# ATmega328P register map
File version: 1.0
Registers are 8-bit, read-write, reset 0x0 unless marked. A register's access mark holds for its fields unless they carry their own. Offsets are from the block's base; [hi:lo] are bit positions; {n}, {i} and the like mark numbered series.

## TC2 — Timer/Counter, 8-bit Async
Base 0x00800000
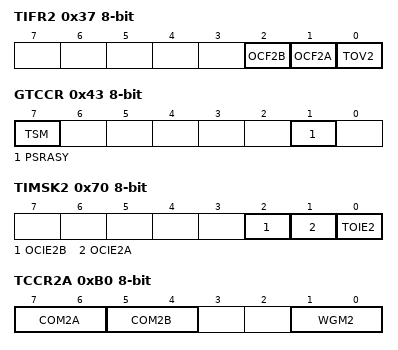
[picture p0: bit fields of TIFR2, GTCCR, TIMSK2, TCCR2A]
0x37 TIFR2 — Timer/Counter Interrupt Flag Register
  [2] OCF2B — Output Compare Flag 2B
  [1] OCF2A — Output Compare Flag 2A
  [0] TOV2 — Timer/Counter2 Overflow Flag
0x43 GTCCR — General Timer Counter Control register
  [7] TSM — Timer/Counter Synchronization Mode
  [1] PSRASY — Prescaler Reset Timer/Counter2
0x70 TIMSK2 — Timer/Counter Interrupt Mask register
  [2] OCIE2B — Timer/Counter2 Output Compare Match B Interrupt Enable
  [1] OCIE2A — Timer/Counter2 Output Compare Match A Interrupt Enable
  [0] TOIE2 — Timer/Counter2 Overflow Interrupt Enable
0xB0 TCCR2A — Timer/Counter2 Control Register A
  [7:6] COM2A — Compare Output Mode bits
  [5:4] COM2B — Compare Output Mode bits
  [1:0] WGM2 — Waveform Genration Mode
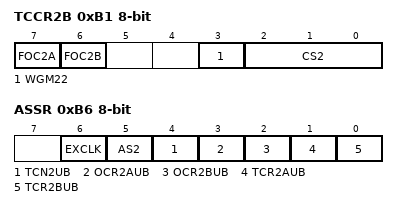
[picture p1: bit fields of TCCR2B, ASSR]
0xB1 TCCR2B — Timer/Counter2 Control Register B
  [7] FOC2A — Force Output Compare A
  [6] FOC2B — Force Output Compare B
  [3] WGM22 — Waveform Generation Mode
  [2:0] CS2 — Clock Select bits
0xB2 TCNT2 — Timer/Counter2
0xB3 OCR2A — Timer/Counter2 Output Compare Register A
0xB4 OCR2B — Timer/Counter2 Output Compare Register B
0xB6 ASSR — Asynchronous Status Register
  [6] EXCLK — Enable External Clock Input
  [5] AS2 — Asynchronous Timer/Counter2
  [4] TCN2UB — Timer/Counter2 Update Busy
  [3] OCR2AUB — Output Compare Register2 Update Busy
  [2] OCR2BUB — Output Compare Register 2 Update Busy
  [1] TCR2AUB — Timer/Counter Control Register2 Update Busy
  [0] TCR2BUB — Timer/Counter Control Register2 Update Busy

## ADC — Analog-to-Digital Converter
Base 0x00800000
0x78 ADC 16-bit (reset mask 0xFF) — ADC Data Register Bytes
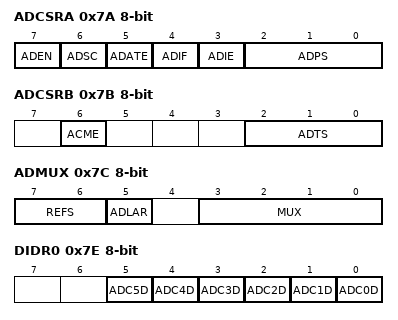
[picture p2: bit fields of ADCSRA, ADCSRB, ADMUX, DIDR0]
0x7A ADCSRA — The ADC Control and Status register A
  [7] ADEN — ADC Enable
  [6] ADSC — ADC Start Conversion
  [5] ADATE — ADC Auto Trigger Enable
  [4] ADIF — ADC Interrupt Flag
  [3] ADIE — ADC Interrupt Enable
  [2:0] ADPS — ADC Prescaler Select Bits
0x7B ADCSRB — The ADC Control and Status register B
  [6] ACME
  [2:0] ADTS — ADC Auto Trigger Source bits
0x7C ADMUX — The ADC multiplexer Selection Register
  [7:6] REFS — Reference Selection Bits
  [5] ADLAR — Left Adjust Result
  [3:0] MUX — Analog Channel Selection Bits
0x7E DIDR0 — Digital Input Disable Register
  [n] ADC{n}D (n=0..5)

## AC — Analog Comparator
Base 0x00800000
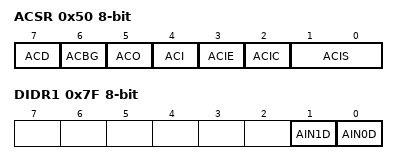
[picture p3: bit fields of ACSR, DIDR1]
0x50 ACSR — Analog Comparator Control And Status Register
  [7] ACD — Analog Comparator Disable
  [6] ACBG — Analog Comparator Bandgap Select
  [5] ACO — Analog Compare Output
  [4] ACI — Analog Comparator Interrupt Flag
  [3] ACIE — Analog Comparator Interrupt Enable
  [2] ACIC — Analog Comparator Input Capture Enable
  [1:0] ACIS — Analog Comparator Interrupt Mode Select bits
0x7F DIDR1 — Digital Input Disable Register 1
  [1] AIN1D — AIN1 Digital Input Disable
  [0] AIN0D — AIN0 Digital Input Disable

## PORTB — I/O Port
Base 0x00800000
0x23 PINB — Port B Input Pins
0x24 DDRB — Port B Data Direction Register
0x25 PORTB — Port B Data Register

## PORTC — I/O Port
Base 0x00800000
0x26 PINC — Port C Input Pins
0x27 DDRC — Port C Data Direction Register
0x28 PORTC — Port C Data Register

## PORTD — I/O Port
Base 0x00800000
0x29 PIND — Port D Input Pins
0x2A DDRD — Port D Data Direction Register
0x2B PORTD — Port D Data Register

## TC0 — Timer/Counter, 8-bit
Base 0x00800000
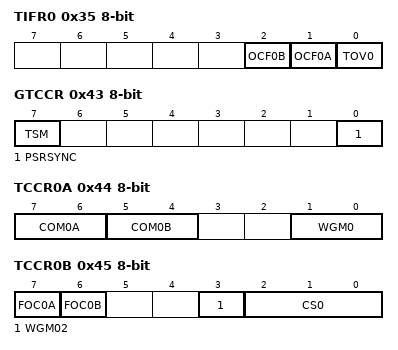
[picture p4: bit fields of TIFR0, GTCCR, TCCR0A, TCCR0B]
0x35 TIFR0 — Timer/Counter0 Interrupt Flag register
  [2] OCF0B — Timer/Counter0 Output Compare Flag 0B
  [1] OCF0A — Timer/Counter0 Output Compare Flag 0A
  [0] TOV0 — Timer/Counter0 Overflow Flag
0x43 GTCCR — General Timer/Counter Control Register
  [7] TSM — Timer/Counter Synchronization Mode
  [0] PSRSYNC — Prescaler Reset Timer/Counter1 and Timer/Counter0
0x44 TCCR0A — Timer/Counter Control Register A
  [7:6] COM0A — Compare Output Mode, Phase Correct PWM Mode
  [5:4] COM0B — Compare Output Mode, Fast PWm
  [1:0] WGM0 — Waveform Generation Mode
0x45 TCCR0B — Timer/Counter Control Register B
  [7] FOC0A — Force Output Compare A
  [6] FOC0B — Force Output Compare B
  [3] WGM02
  [2:0] CS0 — Clock Select
0x46 TCNT0 — Timer/Counter0
0x47 OCR0A — Timer/Counter0 Output Compare Register
0x48 OCR0B — Timer/Counter0 Output Compare Register
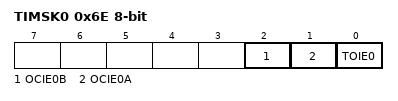
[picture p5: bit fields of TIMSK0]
0x6E TIMSK0 — Timer/Counter0 Interrupt Mask Register
  [2] OCIE0B — Timer/Counter0 Output Compare Match B Interrupt Enable
  [1] OCIE0A — Timer/Counter0 Output Compare Match A Interrupt Enable
  [0] TOIE0 — Timer/Counter0 Overflow Interrupt Enable

## EXINT — External Interrupts
Base 0x00800000
0x3B PCIFR — Pin Change Interrupt Flag Register
  [2:0] PCIF — Pin Change Interrupt Flags
0x3C EIFR — External Interrupt Flag Register
  [1:0] INTF — External Interrupt Flags
0x3D EIMSK — External Interrupt Mask Register
  [1:0] INT — External Interrupt Request 1 Enable
0x68 PCICR — Pin Change Interrupt Control Register
  [2:0] PCIE — Pin Change Interrupt Enables
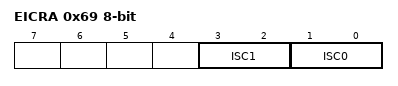
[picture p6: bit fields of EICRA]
0x69 EICRA — External Interrupt Control Register
  [3:2] ISC1 — External Interrupt Sense Control 1 Bits
  [1:0] ISC0 — External Interrupt Sense Control 0 Bits
0x6B PCMSK0 — Pin Change Mask Register 0
  [7:0] PCINT — Pin Change Enable Masks
0x6C PCMSK1 — Pin Change Mask Register 1
  [6:0] PCINT — Pin Change Enable Masks
0x6D PCMSK2 — Pin Change Mask Register 2
  [7:0] PCINT — Pin Change Enable Masks

## SPI — Serial Peripheral Interface
Base 0x00800000
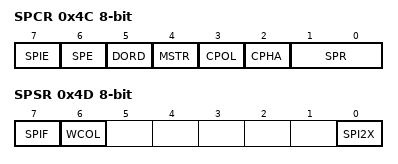
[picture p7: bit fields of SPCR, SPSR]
0x4C SPCR — SPI Control Register
  [7] SPIE — SPI Interrupt Enable
  [6] SPE — SPI Enable
  [5] DORD — Data Order
  [4] MSTR — Master/Slave Select
  [3] CPOL — Clock polarity
  [2] CPHA — Clock Phase
  [1:0] SPR — SPI Clock Rate Selects
0x4D SPSR — SPI Status Register
  [7] SPIF — SPI Interrupt Flag
  [6] WCOL — Write Collision Flag
  [0] SPI2X — Double SPI Speed Bit

## WDT — Watchdog Timer
Base 0x00800000
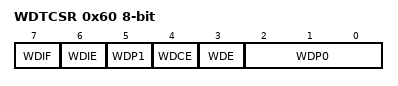
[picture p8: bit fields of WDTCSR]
0x60 WDTCSR — Watchdog Timer Control Register
  [7] WDIF — Watchdog Timeout Interrupt Flag
  [6] WDIE — Watchdog Timeout Interrupt Enable
  [5] WDP1 — Watchdog Timer Prescaler Bits
  [4] WDCE — Watchdog Change Enable
  [3] WDE — Watch Dog Enable
  [2:0] WDP0 — Watchdog Timer Prescaler Bits

## EEPROM
Base 0x00800000
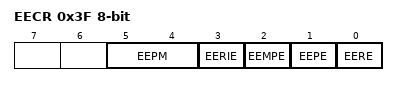
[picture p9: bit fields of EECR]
0x3F EECR — EEPROM Control Register
  [5:4] EEPM — EEPROM Programming Mode Bits
  [3] EERIE — EEPROM Ready Interrupt Enable
  [2] EEMPE — EEPROM Master Write Enable
  [1] EEPE — EEPROM Write Enable
  [0] EERE — EEPROM Read Enable
0x40 EEDR — EEPROM Data Register
0x41 EEAR 16-bit (reset mask 0xFF) — EEPROM Address Register Bytes
